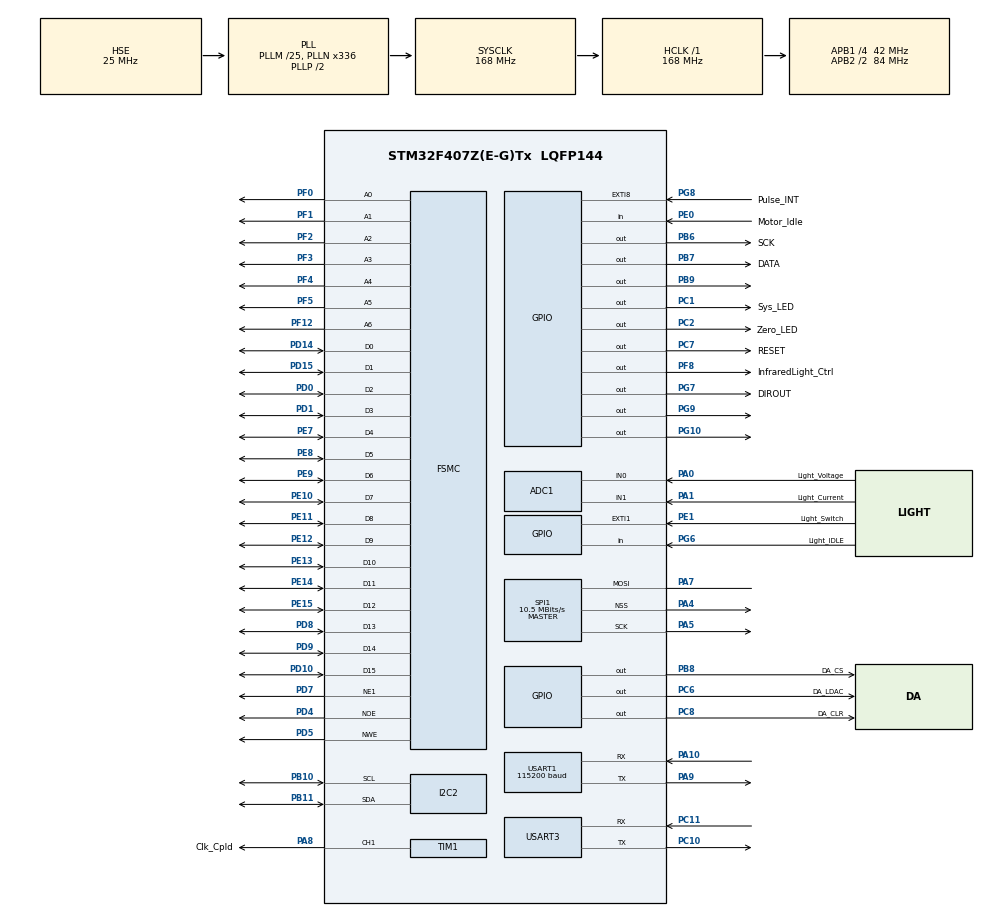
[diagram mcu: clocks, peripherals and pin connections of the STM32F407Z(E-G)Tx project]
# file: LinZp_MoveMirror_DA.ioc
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ADC1.Channel-0\#ChannelRegularConversion=ADC_CHANNEL_0
ADC1.NbrOfConversionFlag=1
ADC1.Rank-0\#ChannelRegularConversion=1
ADC1.SamplingTime-0\#ChannelRegularConversion=ADC_SAMPLETIME_3CYCLES
ADC1.master=1
Dma.I2C2_RX.0.Direction=DMA_PERIPH_TO_MEMORY
Dma.I2C2_RX.0.FIFOMode=DMA_FIFOMODE_DISABLE
Dma.I2C2_RX.0.Instance=DMA1_Stream2
Dma.I2C2_RX.0.MemDataAlignment=DMA_MDATAALIGN_BYTE
Dma.I2C2_RX.0.MemInc=DMA_MINC_ENABLE
Dma.I2C2_RX.0.Mode=DMA_NORMAL
Dma.I2C2_RX.0.PeriphDataAlignment=DMA_PDATAALIGN_BYTE
Dma.I2C2_RX.0.PeriphInc=DMA_PINC_DISABLE
Dma.I2C2_RX.0.Priority=DMA_PRIORITY_LOW
Dma.I2C2_TX.1.Direction=DMA_MEMORY_TO_PERIPH
Dma.I2C2_TX.1.FIFOMode=DMA_FIFOMODE_DISABLE
Dma.I2C2_TX.1.Instance=DMA1_Stream7
Dma.I2C2_TX.1.MemDataAlignment=DMA_MDATAALIGN_BYTE
Dma.I2C2_TX.1.MemInc=DMA_MINC_ENABLE
Dma.I2C2_TX.1.Mode=DMA_NORMAL
Dma.I2C2_TX.1.PeriphDataAlignment=DMA_PDATAALIGN_BYTE
Dma.I2C2_TX.1.PeriphInc=DMA_PINC_DISABLE
Dma.I2C2_TX.1.Priority=DMA_PRIORITY_LOW
Dma.Request0=I2C2_RX
Dma.Request1=I2C2_TX
Mcu.Family=STM32F4
Mcu.Name=STM32F407Z(E-G)Tx
Mcu.Package=LQFP144
NVIC.DMA1_Stream2_IRQn=true\:0\:0\:false\:false\:true\:false\:true
NVIC.DMA1_Stream7_IRQn=true\:0\:0\:false\:false\:false\:false\:false
NVIC.EXTI1_IRQn=true\:2\:0\:true\:false\:true\:true\:true
NVIC.EXTI9_5_IRQn=true\:1\:0\:true\:false\:true\:true\:true
NVIC.PriorityGroup=NVIC_PRIORITYGROUP_3
NVIC.TIM3_IRQn=true\:3\:0\:true\:false\:true\:true\:true
NVIC.TIM4_IRQn=true\:4\:0\:true\:false\:true\:true\:true
NVIC.USART1_IRQn=true\:0\:0\:true\:false\:true\:true\:true
NVIC.USART3_IRQn=true\:0\:0\:false\:false\:true\:true\:true
PA0-WKUP.GPIO_Label=Light_Voltage
PA0-WKUP.Signal=ADCx_IN0
PA1.GPIO_Label=Light_Current
PA1.Signal=ADCx_IN1
PA10.Mode=Asynchronous
PA10.Signal=USART1_RX
PA4.Mode=NSS_Signal_Hard_Output
PA4.Signal=SPI1_NSS
PA5.Mode=Simplex_Bidirectional_Master
PA5.Signal=SPI1_SCK
PA7.Mode=Simplex_Bidirectional_Master
PA7.Signal=SPI1_MOSI
PA8.GPIO_Label=Clk_Cpld
PA8.GPIO_Speed=GPIO_SPEED_FREQ_VERY_HIGH
PA8.Signal=S_TIM1_CH1
PA9.Mode=Asynchronous
PA9.Signal=USART1_TX
PB10.Mode=I2C
PB10.Signal=I2C2_SCL
PB11.Mode=I2C
PB11.Signal=I2C2_SDA
PB6.GPIO_Label=SCK
PB6.GPIO_Speed=GPIO_SPEED_FREQ_VERY_HIGH
PB6.Signal=GPIO_Output
PB7.GPIO_Label=DATA
PB7.GPIO_Speed=GPIO_SPEED_FREQ_VERY_HIGH
PB7.Signal=GPIO_Output
PB8.GPIO_Label=DA_CS
PB8.Signal=GPIO_Output
PB9.GPIO_PuPd=GPIO_NOPULL
PB9.GPIO_Speed=GPIO_SPEED_FREQ_VERY_HIGH
PB9.PinState=GPIO_PIN_RESET
PB9.Signal=GPIO_Output
PC1.GPIO_Label=Sys_LED
PC1.GPIO_PuPd=GPIO_PULLUP
PC1.GPIO_Speed=GPIO_SPEED_FREQ_HIGH
PC1.PinState=GPIO_PIN_SET
PC1.Signal=GPIO_Output
PC10.Mode=Asynchronous
PC10.Signal=USART3_TX
PC11.Mode=Asynchronous
PC11.Signal=USART3_RX
PC2.GPIO_Label=Zero_LED
PC2.GPIO_PuPd=GPIO_PULLUP
PC2.GPIO_Speed=GPIO_SPEED_FREQ_HIGH
PC2.PinState=GPIO_PIN_SET
PC2.Signal=GPIO_Output
PC6.GPIO_Label=DA_LDAC
PC6.Signal=GPIO_Output
PC7.GPIO_Label=RESET
PC7.Signal=GPIO_Output
PC8.GPIO_Label=DA_CLR
PC8.Signal=GPIO_Output
PD0.Signal=FSMC_D2_DA2
PD1.Signal=FSMC_D3_DA3
PD10.Signal=FSMC_D15_DA15
PD14.Signal=FSMC_D0_DA0
PD15.Signal=FSMC_D1_DA1
PD4.Signal=FSMC_NOE
PD5.Signal=FSMC_NWE
PD7.Mode=NorPsramChipSelect1_1
PD7.Signal=FSMC_NE1
PD8.Signal=FSMC_D13_DA13
PD9.Signal=FSMC_D14_DA14
PE0.GPIO_Label=Motor_Idle
PE0.GPIO_PuPd=GPIO_PULLUP
PE0.Signal=GPIO_Input
PE1.GPIO_Label=Light_Switch
PE1.Signal=GPXTI1
PE10.Signal=FSMC_D7_DA7
PE11.Signal=FSMC_D8_DA8
PE12.Signal=FSMC_D9_DA9
PE13.Signal=FSMC_D10_DA10
PE14.Signal=FSMC_D11_DA11
PE15.Signal=FSMC_D12_DA12
PE7.Signal=FSMC_D4_DA4
PE8.Signal=FSMC_D5_DA5
PE9.Signal=FSMC_D6_DA6
PF0.Signal=FSMC_A0
PF1.Signal=FSMC_A1
PF12.Signal=FSMC_A6
PF2.Signal=FSMC_A2
PF3.Signal=FSMC_A3
PF4.Signal=FSMC_A4
PF5.Signal=FSMC_A5
PF8.GPIO_Label=InfraredLight_Ctrl
PF8.GPIO_PuPd=GPIO_PULLDOWN
PF8.Signal=GPIO_Output
PG10.Signal=GPIO_Output
PG6.GPIO_Label=Light_IDLE
PG6.GPIO_PuPd=GPIO_PULLUP
PG6.Signal=GPIO_Input
PG7.GPIO_Label=DIROUT
PG7.GPIO_PuPd=GPIO_NOPULL
PG7.GPIO_Speed=GPIO_SPEED_FREQ_VERY_HIGH
PG7.Signal=GPIO_Output
PG8.GPIO_Label=Pulse_INT
PG8.Signal=GPXTI8
PG9.Signal=GPIO_Output
PH0-OSC_IN.Mode=HSE-External-Oscillator
PH0-OSC_IN.Signal=RCC_OSC_IN
PH1-OSC_OUT.Mode=HSE-External-Oscillator
PH1-OSC_OUT.Signal=RCC_OSC_OUT
ProjectManager.HeapSize=0x200
ProjectManager.StackSize=0x400
ProjectManager.TargetToolchain=MDK-ARM V5
RCC.48MHZClocksFreq_Value=84000000
RCC.AHBFreq_Value=168000000
RCC.APB1CLKDivider=RCC_HCLK_DIV4
RCC.APB1Freq_Value=42000000
RCC.APB1TimFreq_Value=84000000
RCC.APB2CLKDivider=RCC_HCLK_DIV2
RCC.APB2Freq_Value=84000000
RCC.APB2TimFreq_Value=168000000
RCC.CortexFreq_Value=168000000
RCC.HCLKFreq_Value=168000000
RCC.HSE_VALUE=25000000
RCC.HSI_VALUE=16000000
RCC.LSE_VALUE=32768
RCC.PLLM=25
RCC.PLLN=336
RCC.PLLSourceVirtual=RCC_PLLSOURCE_HSE
RCC.SYSCLKFreq_VALUE=168000000
RCC.SYSCLKSource=RCC_SYSCLKSOURCE_PLLCLK
RCC.VCOOutputFreq_Value=336000000
SH.ADCx_IN0.0=ADC1_IN0,IN0
SH.ADCx_IN1.0=ADC1_IN1,IN1
SH.FSMC_A0.0=FSMC_A0,7b-a1
SH.FSMC_A1.0=FSMC_A1,7b-a1
SH.FSMC_A2.0=FSMC_A2,7b-a1
SH.FSMC_A3.0=FSMC_A3,7b-a1
SH.FSMC_A4.0=FSMC_A4,7b-a1
SH.FSMC_A5.0=FSMC_A5,7b-a1
SH.FSMC_A6.0=FSMC_A6,7b-a1
SH.FSMC_D0_DA0.0=FSMC_D0,16b-d1
SH.FSMC_D10_DA10.0=FSMC_D10,16b-d1
SH.FSMC_D11_DA11.0=FSMC_D11,16b-d1
SH.FSMC_D12_DA12.0=FSMC_D12,16b-d1
SH.FSMC_D13_DA13.0=FSMC_D13,16b-d1
SH.FSMC_D14_DA14.0=FSMC_D14,16b-d1
SH.FSMC_D15_DA15.0=FSMC_D15,16b-d1
SH.FSMC_D1_DA1.0=FSMC_D1,16b-d1
SH.FSMC_D2_DA2.0=FSMC_D2,16b-d1
SH.FSMC_D3_DA3.0=FSMC_D3,16b-d1
SH.FSMC_D4_DA4.0=FSMC_D4,16b-d1
SH.FSMC_D5_DA5.0=FSMC_D5,16b-d1
SH.FSMC_D6_DA6.0=FSMC_D6,16b-d1
SH.FSMC_D7_DA7.0=FSMC_D7,16b-d1
SH.FSMC_D8_DA8.0=FSMC_D8,16b-d1
SH.FSMC_D9_DA9.0=FSMC_D9,16b-d1
SH.FSMC_NOE.0=FSMC_NOE,Sram1
SH.FSMC_NWE.0=FSMC_NWE,Sram1
SH.S_TIM1_CH1.0=TIM1_CH1,PWM Generation1 CH1
SPI1.BaudRatePrescaler=SPI_BAUDRATEPRESCALER_8
SPI1.CLKPhase=SPI_PHASE_2EDGE
SPI1.CalculateBaudRate=10.5 MBits/s
SPI1.Direction=SPI_DIRECTION_1LINE
SPI1.Mode=SPI_MODE_MASTER
SPI1.VirtualNSS=VM_NSSHARD
SPI1.VirtualType=VM_MASTER
TIM1.Channel-PWM\ Generation1\ CH1=TIM_CHANNEL_1
TIM1.Period=4
TIM1.Pulse-PWM\ Generation1\ CH1=2
TIM3.Period=1
TIM3.Prescaler=84
TIM4.Period=1
TIM4.Prescaler=84
USART1.BaudRate=115200
USART1.OverSampling=UART_OVERSAMPLING_8
USART1.VirtualMode=VM_ASYNC
USART3.OverSampling=UART_OVERSAMPLING_8
USART3.VirtualMode=VM_ASYNC
VP_TIM1_VS_ClockSourceINT.Mode=Internal
VP_TIM3_VS_ClockSourceINT.Mode=Internal
VP_TIM4_VS_ClockSourceINT.Mode=Internal
board=MoveMirrorFinal_pwm

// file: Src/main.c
/* USER CODE BEGIN Header */
/**
  ******************************************************************************
  * @file           : main.c
  * @brief          : Main program body
  ******************************************************************************
  * @attention
  *
  * <h2><center>&copy; Copyright (c) 2019 STMicroelectronics.
  * All rights reserved.</center></h2>
  *
  * This software component is licensed by ST under BSD 3-Clause license,
  * the "License"; You may not use this file except in compliance with the
  * License. You may obtain a copy of the License at:
  *                        opensource.org/licenses/BSD-3-Clause
  *
  ******************************************************************************
  */
/* USER CODE END Header */

#include "main.h"

/* USER CODE BEGIN Includes */
#include "sys.h"
/* USER CODE END Includes */

ADC_HandleTypeDef hadc1;

I2C_HandleTypeDef hi2c2;
DMA_HandleTypeDef hdma_i2c2_rx;
DMA_HandleTypeDef hdma_i2c2_tx;

SPI_HandleTypeDef hspi1;

TIM_HandleTypeDef htim1;
TIM_HandleTypeDef htim3;
TIM_HandleTypeDef htim4;

UART_HandleTypeDef huart1;
UART_HandleTypeDef huart3;

SRAM_HandleTypeDef hsram1;

/* USER CODE BEGIN PV */
/* Private variables ---------------------------------------------------------*/

/* USER CODE END PV */

void SystemClock_Config(void);
static void MX_GPIO_Init(void);
static void MX_DMA_Init(void);
static void MX_FSMC_Init(void);
static void MX_USART1_UART_Init(void);
static void MX_TIM3_Init(void);
static void MX_TIM4_Init(void);
static void MX_SPI1_Init(void);
static void MX_TIM1_Init(void);
static void MX_I2C2_Init(void);
static void MX_USART3_UART_Init(void);
static void MX_ADC1_Init(void);
/* USER CODE BEGIN PFP */
/* Private function prototypes -----------------------------------------------*/

/* USER CODE END PFP */

int main(void)
{

  /* MCU Configuration--------------------------------------------------------*/

  /* Reset of all peripherals, Initializes the Flash interface and the Systick. */
  HAL_Init();

  /* Configure the system clock */
  SystemClock_Config();

  /* Initialize all configured peripherals */
  MX_GPIO_Init();
  MX_DMA_Init();
  MX_FSMC_Init();
  MX_USART1_UART_Init();
  MX_TIM3_Init();
  MX_TIM4_Init();
  MX_SPI1_Init();
  MX_TIM1_Init();
  MX_I2C2_Init();
  MX_USART3_UART_Init();
  MX_ADC1_Init();
  /* USER CODE BEGIN 2 */
	DAC_init();

	HAL_UART_Receive_IT(&huart1,&Uart1_Data,1);//给接收到的数据定向，存在Uart1_Data_buffer[10]//__HAL_UART_ENABLE_IT(&huart1,UART_IT_RXNE); //开启接收完成中断
	HAL_UART_Receive_IT(&huart3,&Uart3_Data,1);//给接收到的数据定向，存在Uart1_Data_buffer[10]//__HAL_UART_ENABLE_IT(&huart1,UART_IT_RXNE); //开启接收完成中断

	//HAL_Delay_ms(15000);
	////////////////////////////////////////////////////////////////////////////
	HAL_TIM_PWM_Start(&htim1,TIM_CHANNEL_1);//提供给cpld时钟，实测33.6015MHz
	AD5245_Write(LightIntensity);//给AD5245写入初始值0x35=53，6.4v//8是10.6V//255是3.7v//0是12.43v
	//HAL_TIM_PWM_Start(&htim8,TIM_CHANNEL_1);//tim8开启 PWM 通道 1
	ResetCount = 0;       //复位计数
	ProcessFlag=ResetFlag;//开机复位
	//ProcessFlag=DebugFlag;//开机复位
	SystemReset();
	HAL_TIM_Base_Start_IT(&htim3);   //tim3中断开启,用于动镜的加速和减速
	HAL_TIM_Base_Start_IT(&htim4);   //tim4中断开启，用于调试信息输出，以及运动失调的复位
  /* USER CODE END 2 */

  /* Infinite loop */
  while (1)
  {

    /* USER CODE BEGIN 3 */
//		HAL_GPIO_WritePin(GPIOB, GPIO_PIN_9, GPIO_PIN_RESET);
//		HAL_Delay_ms(100);
//		HAL_GPIO_WritePin(GPIOB, GPIO_PIN_9, GPIO_PIN_RESET);
//		HAL_Delay_ms(100);
//AD5245_Write(0);//给AD5245写入初始值0x35=53，6.4v//8是10.6V//255是3.7v//0是12.43v
//GetLightStatus();

//HAL_Delay_ms(100);
//	Motor_Idle=HAL_GPIO_ReadPin(Motor_Idle_GPIO_Port,Motor_Idle_Pin);
//	Light_Idle=HAL_GPIO_ReadPin(Light_IDLE_GPIO_Port,Light_IDLE_Pin);
//char str[25];
//sprintf(str,"who is your daddy\r\n");
//HAL_UART_Transmit(&huart3,(uint8_t*)str,strlen(str),1000);

//	HAL_Delay_ms(10);
//	HAL_GPIO_WritePin(GPIOB, GPIO_PIN_6, GPIO_PIN_RESET); //SHT_SCK=1
//	HAL_GPIO_WritePin(GPIOB, GPIO_PIN_7, GPIO_PIN_RESET);//SHT_SCK=0
//	HAL_GPIO_WritePin(GPIOB, GPIO_PIN_9, GPIO_PIN_RESET);
//
//
//	HAL_Delay_ms(10);
//	HAL_GPIO_WritePin(GPIOB, GPIO_PIN_6, GPIO_PIN_SET); //SHT_SCK=1
//	HAL_GPIO_WritePin(GPIOB, GPIO_PIN_7, GPIO_PIN_SET);//SHT_SCK=0
//	HAL_GPIO_WritePin(GPIOB, GPIO_PIN_9, GPIO_PIN_SET);

//float *p_temp,*p_humi;
//p_temp=&temp;
//p_humi=&humi;
//ShtMeasure(p_temp,p_humi);

//SetOutput(-584287);

//uint8_t ADDR_AD5245_Write = 0x58;//01011000
//uint8_t data = 0x35;//53
//HAL_I2C_Mem_Write(&hi2c1, ADDR_AD5245_Write, 0, I2C_MEMADD_SIZE_8BIT,&data,1,0xff);
//HAL_I2C_Master_Transmit_DMA(&hi2c1,ADDR_AD5245_Write,&data,1);

//ADC_Value4 = Get_Adc(4);
//ADC_Value5 = Get_Adc(5);

//HAL_Delay(5);
//HAL_I2C_Mem_Write(&hi2c1, ADDR_24LCxx_Read, 0, I2C_MEMADD_SIZE_8BIT,&val,1,0xff);

//SetOutput(300000);
//Write_AD_5791(320000);
//HAL_Delay_ms(1000);
//HAL_GPIO_WritePin(GPIOC, GPIO_PIN_1, GPIO_PIN_RESET);
//HAL_Delay_ms(1000);
//HAL_GPIO_WritePin(GPIOC, GPIO_PIN_1, GPIO_PIN_SET);
  }
  /* USER CODE END 3 */
}

void SystemClock_Config(void)
{
  RCC_OscInitTypeDef RCC_OscInitStruct = {0};
  RCC_ClkInitTypeDef RCC_ClkInitStruct = {0};

  /** Configure the main internal regulator output voltage
  */
  __HAL_RCC_PWR_CLK_ENABLE();
  __HAL_PWR_VOLTAGESCALING_CONFIG(PWR_REGULATOR_VOLTAGE_SCALE1);
  /** Initializes the CPU, AHB and APB busses clocks
  */
  RCC_OscInitStruct.OscillatorType = RCC_OSCILLATORTYPE_HSE;
  RCC_OscInitStruct.HSEState = RCC_HSE_ON;
  RCC_OscInitStruct.PLL.PLLState = RCC_PLL_ON;
  RCC_OscInitStruct.PLL.PLLSource = RCC_PLLSOURCE_HSE;
  RCC_OscInitStruct.PLL.PLLM = 25;
  RCC_OscInitStruct.PLL.PLLN = 336;
  RCC_OscInitStruct.PLL.PLLP = RCC_PLLP_DIV2;
  RCC_OscInitStruct.PLL.PLLQ = 4;
  if (HAL_RCC_OscConfig(&RCC_OscInitStruct) != HAL_OK)
  {
    Error_Handler();
  }
  /** Initializes the CPU, AHB and APB busses clocks
  */
  RCC_ClkInitStruct.ClockType = RCC_CLOCKTYPE_HCLK|RCC_CLOCKTYPE_SYSCLK
                              |RCC_CLOCKTYPE_PCLK1|RCC_CLOCKTYPE_PCLK2;
  RCC_ClkInitStruct.SYSCLKSource = RCC_SYSCLKSOURCE_PLLCLK;
  RCC_ClkInitStruct.AHBCLKDivider = RCC_SYSCLK_DIV1;
  RCC_ClkInitStruct.APB1CLKDivider = RCC_HCLK_DIV4;
  RCC_ClkInitStruct.APB2CLKDivider = RCC_HCLK_DIV2;

  if (HAL_RCC_ClockConfig(&RCC_ClkInitStruct, FLASH_LATENCY_5) != HAL_OK)
  {
    Error_Handler();
  }
}

static void MX_ADC1_Init(void)
{

  ADC_ChannelConfTypeDef sConfig = {0};

  /** Configure the global features of the ADC (Clock, Resolution, Data Alignment and number of conversion)
  */
  hadc1.Instance = ADC1;
  hadc1.Init.ClockPrescaler = ADC_CLOCK_SYNC_PCLK_DIV4;
  hadc1.Init.Resolution = ADC_RESOLUTION_12B;
  hadc1.Init.ScanConvMode = DISABLE;
  hadc1.Init.ContinuousConvMode = DISABLE;
  hadc1.Init.DiscontinuousConvMode = DISABLE;
  hadc1.Init.ExternalTrigConvEdge = ADC_EXTERNALTRIGCONVEDGE_NONE;
  hadc1.Init.ExternalTrigConv = ADC_SOFTWARE_START;
  hadc1.Init.DataAlign = ADC_DATAALIGN_RIGHT;
  hadc1.Init.NbrOfConversion = 1;
  hadc1.Init.DMAContinuousRequests = DISABLE;
  hadc1.Init.EOCSelection = ADC_EOC_SINGLE_CONV;
  if (HAL_ADC_Init(&hadc1) != HAL_OK)
  {
    Error_Handler();
  }
  /** Configure for the selected ADC regular channel its corresponding rank in the sequencer and its sample time.
  */
  sConfig.Channel = ADC_CHANNEL_0;
  sConfig.Rank = 1;
  sConfig.SamplingTime = ADC_SAMPLETIME_3CYCLES;
  if (HAL_ADC_ConfigChannel(&hadc1, &sConfig) != HAL_OK)
  {
    Error_Handler();
  }

}

static void MX_I2C2_Init(void)
{

  hi2c2.Instance = I2C2;
  hi2c2.Init.ClockSpeed = 100000;
  hi2c2.Init.DutyCycle = I2C_DUTYCYCLE_2;
  hi2c2.Init.OwnAddress1 = 0;
  hi2c2.Init.AddressingMode = I2C_ADDRESSINGMODE_7BIT;
  hi2c2.Init.DualAddressMode = I2C_DUALADDRESS_DISABLE;
  hi2c2.Init.OwnAddress2 = 0;
  hi2c2.Init.GeneralCallMode = I2C_GENERALCALL_DISABLE;
  hi2c2.Init.NoStretchMode = I2C_NOSTRETCH_DISABLE;
  if (HAL_I2C_Init(&hi2c2) != HAL_OK)
  {
    Error_Handler();
  }

}

static void MX_SPI1_Init(void)
{

  /* SPI1 parameter configuration*/
  hspi1.Instance = SPI1;
  hspi1.Init.Mode = SPI_MODE_MASTER;
  hspi1.Init.Direction = SPI_DIRECTION_1LINE;
  hspi1.Init.DataSize = SPI_DATASIZE_8BIT;
  hspi1.Init.CLKPolarity = SPI_POLARITY_LOW;
  hspi1.Init.CLKPhase = SPI_PHASE_2EDGE;
  hspi1.Init.NSS = SPI_NSS_HARD_OUTPUT;
  hspi1.Init.BaudRatePrescaler = SPI_BAUDRATEPRESCALER_8;
  hspi1.Init.FirstBit = SPI_FIRSTBIT_MSB;
  hspi1.Init.TIMode = SPI_TIMODE_DISABLE;
  hspi1.Init.CRCCalculation = SPI_CRCCALCULATION_DISABLE;
  hspi1.Init.CRCPolynomial = 10;
  if (HAL_SPI_Init(&hspi1) != HAL_OK)
  {
    Error_Handler();
  }

}

static void MX_TIM1_Init(void)
{

  TIM_ClockConfigTypeDef sClockSourceConfig = {0};
  TIM_MasterConfigTypeDef sMasterConfig = {0};
  TIM_OC_InitTypeDef sConfigOC = {0};
  TIM_BreakDeadTimeConfigTypeDef sBreakDeadTimeConfig = {0};

  htim1.Instance = TIM1;
  htim1.Init.Prescaler = 0;
  htim1.Init.CounterMode = TIM_COUNTERMODE_UP;
  htim1.Init.Period = 4;
  htim1.Init.ClockDivision = TIM_CLOCKDIVISION_DIV1;
  htim1.Init.RepetitionCounter = 0;
  htim1.Init.AutoReloadPreload = TIM_AUTORELOAD_PRELOAD_DISABLE;
  if (HAL_TIM_Base_Init(&htim1) != HAL_OK)
  {
    Error_Handler();
  }
  sClockSourceConfig.ClockSource = TIM_CLOCKSOURCE_INTERNAL;
  if (HAL_TIM_ConfigClockSource(&htim1, &sClockSourceConfig) != HAL_OK)
  {
    Error_Handler();
  }
  if (HAL_TIM_PWM_Init(&htim1) != HAL_OK)
  {
    Error_Handler();
  }
  sMasterConfig.MasterOutputTrigger = TIM_TRGO_RESET;
  sMasterConfig.MasterSlaveMode = TIM_MASTERSLAVEMODE_DISABLE;
  if (HAL_TIMEx_MasterConfigSynchronization(&htim1, &sMasterConfig) != HAL_OK)
  {
    Error_Handler();
  }
  sConfigOC.OCMode = TIM_OCMODE_PWM1;
  sConfigOC.Pulse = 2;
  sConfigOC.OCPolarity = TIM_OCPOLARITY_HIGH;
  sConfigOC.OCNPolarity = TIM_OCNPOLARITY_HIGH;
  sConfigOC.OCFastMode = TIM_OCFAST_DISABLE;
  sConfigOC.OCIdleState = TIM_OCIDLESTATE_RESET;
  sConfigOC.OCNIdleState = TIM_OCNIDLESTATE_RESET;
  if (HAL_TIM_PWM_ConfigChannel(&htim1, &sConfigOC, TIM_CHANNEL_1) != HAL_OK)
  {
    Error_Handler();
  }
  sBreakDeadTimeConfig.OffStateRunMode = TIM_OSSR_DISABLE;
  sBreakDeadTimeConfig.OffStateIDLEMode = TIM_OSSI_DISABLE;
  sBreakDeadTimeConfig.LockLevel = TIM_LOCKLEVEL_OFF;
  sBreakDeadTimeConfig.DeadTime = 0;
  sBreakDeadTimeConfig.BreakState = TIM_BREAK_DISABLE;
  sBreakDeadTimeConfig.BreakPolarity = TIM_BREAKPOLARITY_HIGH;
  sBreakDeadTimeConfig.AutomaticOutput = TIM_AUTOMATICOUTPUT_DISABLE;
  if (HAL_TIMEx_ConfigBreakDeadTime(&htim1, &sBreakDeadTimeConfig) != HAL_OK)
  {
    Error_Handler();
  }
  HAL_TIM_MspPostInit(&htim1);

}

static void MX_TIM3_Init(void)
{

  TIM_ClockConfigTypeDef sClockSourceConfig = {0};
  TIM_MasterConfigTypeDef sMasterConfig = {0};

  htim3.Instance = TIM3;
  htim3.Init.Prescaler = 84;
  htim3.Init.CounterMode = TIM_COUNTERMODE_UP;
  htim3.Init.Period = 1;
  htim3.Init.ClockDivision = TIM_CLOCKDIVISION_DIV1;
  htim3.Init.AutoReloadPreload = TIM_AUTORELOAD_PRELOAD_DISABLE;
  if (HAL_TIM_Base_Init(&htim3) != HAL_OK)
  {
    Error_Handler();
  }
  sClockSourceConfig.ClockSource = TIM_CLOCKSOURCE_INTERNAL;
  if (HAL_TIM_ConfigClockSource(&htim3, &sClockSourceConfig) != HAL_OK)
  {
    Error_Handler();
  }
  sMasterConfig.MasterOutputTrigger = TIM_TRGO_RESET;
  sMasterConfig.MasterSlaveMode = TIM_MASTERSLAVEMODE_DISABLE;
  if (HAL_TIMEx_MasterConfigSynchronization(&htim3, &sMasterConfig) != HAL_OK)
  {
    Error_Handler();
  }

}

static void MX_TIM4_Init(void)
{

  TIM_ClockConfigTypeDef sClockSourceConfig = {0};
  TIM_MasterConfigTypeDef sMasterConfig = {0};

  htim4.Instance = TIM4;
  htim4.Init.Prescaler = 84;
  htim4.Init.CounterMode = TIM_COUNTERMODE_UP;
  htim4.Init.Period = 1;
  htim4.Init.ClockDivision = TIM_CLOCKDIVISION_DIV1;
  htim4.Init.AutoReloadPreload = TIM_AUTORELOAD_PRELOAD_DISABLE;
  if (HAL_TIM_Base_Init(&htim4) != HAL_OK)
  {
    Error_Handler();
  }
  sClockSourceConfig.ClockSource = TIM_CLOCKSOURCE_INTERNAL;
  if (HAL_TIM_ConfigClockSource(&htim4, &sClockSourceConfig) != HAL_OK)
  {
    Error_Handler();
  }
  sMasterConfig.MasterOutputTrigger = TIM_TRGO_RESET;
  sMasterConfig.MasterSlaveMode = TIM_MASTERSLAVEMODE_DISABLE;
  if (HAL_TIMEx_MasterConfigSynchronization(&htim4, &sMasterConfig) != HAL_OK)
  {
    Error_Handler();
  }

}

static void MX_USART1_UART_Init(void)
{

  huart1.Instance = USART1;
  huart1.Init.BaudRate = 115200;
  huart1.Init.WordLength = UART_WORDLENGTH_8B;
  huart1.Init.StopBits = UART_STOPBITS_1;
  huart1.Init.Parity = UART_PARITY_NONE;
  huart1.Init.Mode = UART_MODE_TX_RX;
  huart1.Init.HwFlowCtl = UART_HWCONTROL_NONE;
  huart1.Init.OverSampling = UART_OVERSAMPLING_8;
  if (HAL_UART_Init(&huart1) != HAL_OK)
  {
    Error_Handler();
  }

}

static void MX_USART3_UART_Init(void)
{

  huart3.Instance = USART3;
  huart3.Init.BaudRate = 115200;
  huart3.Init.WordLength = UART_WORDLENGTH_8B;
  huart3.Init.StopBits = UART_STOPBITS_1;
  huart3.Init.Parity = UART_PARITY_NONE;
  huart3.Init.Mode = UART_MODE_TX_RX;
  huart3.Init.HwFlowCtl = UART_HWCONTROL_NONE;
  huart3.Init.OverSampling = UART_OVERSAMPLING_8;
  if (HAL_UART_Init(&huart3) != HAL_OK)
  {
    Error_Handler();
  }

}

static void MX_DMA_Init(void)
{
  /* DMA controller clock enable */
  __HAL_RCC_DMA1_CLK_ENABLE();

  /* DMA interrupt init */
  /* DMA1_Stream2_IRQn interrupt configuration */
  HAL_NVIC_SetPriority(DMA1_Stream2_IRQn, 0, 0);
  HAL_NVIC_EnableIRQ(DMA1_Stream2_IRQn);
  /* DMA1_Stream7_IRQn interrupt configuration */
  HAL_NVIC_SetPriority(DMA1_Stream7_IRQn, 0, 0);
  HAL_NVIC_EnableIRQ(DMA1_Stream7_IRQn);

}

static void MX_GPIO_Init(void)
{
  GPIO_InitTypeDef GPIO_InitStruct = {0};

  /* GPIO Ports Clock Enable */
  __HAL_RCC_GPIOF_CLK_ENABLE();
  __HAL_RCC_GPIOH_CLK_ENABLE();
  __HAL_RCC_GPIOC_CLK_ENABLE();
  __HAL_RCC_GPIOA_CLK_ENABLE();
  __HAL_RCC_GPIOE_CLK_ENABLE();
  __HAL_RCC_GPIOB_CLK_ENABLE();
  __HAL_RCC_GPIOD_CLK_ENABLE();
  __HAL_RCC_GPIOG_CLK_ENABLE();

  /*Configure GPIO pin Output Level */
  HAL_GPIO_WritePin(InfraredLight_Ctrl_GPIO_Port, InfraredLight_Ctrl_Pin, GPIO_PIN_RESET);

  /*Configure GPIO pin Output Level */
  HAL_GPIO_WritePin(GPIOC, Sys_LED_Pin|Zero_LED_Pin, GPIO_PIN_SET);

  /*Configure GPIO pin Output Level */
  HAL_GPIO_WritePin(GPIOG, DIROUT_Pin|GPIO_PIN_9|GPIO_PIN_10, GPIO_PIN_RESET);

  /*Configure GPIO pin Output Level */
  HAL_GPIO_WritePin(GPIOC, DA_LDAC_Pin|RESET_Pin|DA_CLR_Pin, GPIO_PIN_RESET);

  /*Configure GPIO pin Output Level */
  HAL_GPIO_WritePin(GPIOB, SCK_Pin|DATA_Pin|DA_CS_Pin|GPIO_PIN_9, GPIO_PIN_RESET);

  /*Configure GPIO pin : InfraredLight_Ctrl_Pin */
  GPIO_InitStruct.Pin = InfraredLight_Ctrl_Pin;
  GPIO_InitStruct.Mode = GPIO_MODE_OUTPUT_PP;
  GPIO_InitStruct.Pull = GPIO_PULLDOWN;
  GPIO_InitStruct.Speed = GPIO_SPEED_FREQ_LOW;
  HAL_GPIO_Init(InfraredLight_Ctrl_GPIO_Port, &GPIO_InitStruct);

  /*Configure GPIO pins : Sys_LED_Pin Zero_LED_Pin */
  GPIO_InitStruct.Pin = Sys_LED_Pin|Zero_LED_Pin;
  GPIO_InitStruct.Mode = GPIO_MODE_OUTPUT_PP;
  GPIO_InitStruct.Pull = GPIO_PULLUP;
  GPIO_InitStruct.Speed = GPIO_SPEED_FREQ_HIGH;
  HAL_GPIO_Init(GPIOC, &GPIO_InitStruct);

  /*Configure GPIO pin : Light_IDLE_Pin */
  GPIO_InitStruct.Pin = Light_IDLE_Pin;
  GPIO_InitStruct.Mode = GPIO_MODE_INPUT;
  GPIO_InitStruct.Pull = GPIO_PULLUP;
  HAL_GPIO_Init(Light_IDLE_GPIO_Port, &GPIO_InitStruct);

  /*Configure GPIO pin : DIROUT_Pin */
  GPIO_InitStruct.Pin = DIROUT_Pin;
  GPIO_InitStruct.Mode = GPIO_MODE_OUTPUT_PP;
  GPIO_InitStruct.Pull = GPIO_NOPULL;
  GPIO_InitStruct.Speed = GPIO_SPEED_FREQ_VERY_HIGH;
  HAL_GPIO_Init(DIROUT_GPIO_Port, &GPIO_InitStruct);

  /*Configure GPIO pin : Pulse_INT_Pin */
  GPIO_InitStruct.Pin = Pulse_INT_Pin;
  GPIO_InitStruct.Mode = GPIO_MODE_IT_RISING;
  GPIO_InitStruct.Pull = GPIO_NOPULL;
  HAL_GPIO_Init(Pulse_INT_GPIO_Port, &GPIO_InitStruct);

  /*Configure GPIO pins : DA_LDAC_Pin RESET_Pin DA_CLR_Pin */
  GPIO_InitStruct.Pin = DA_LDAC_Pin|RESET_Pin|DA_CLR_Pin;
  GPIO_InitStruct.Mode = GPIO_MODE_OUTPUT_PP;
  GPIO_InitStruct.Pull = GPIO_NOPULL;
  GPIO_InitStruct.Speed = GPIO_SPEED_FREQ_LOW;
  HAL_GPIO_Init(GPIOC, &GPIO_InitStruct);

  /*Configure GPIO pins : PG9 PG10 */
  GPIO_InitStruct.Pin = GPIO_PIN_9|GPIO_PIN_10;
  GPIO_InitStruct.Mode = GPIO_MODE_OUTPUT_PP;
  GPIO_InitStruct.Pull = GPIO_NOPULL;
  GPIO_InitStruct.Speed = GPIO_SPEED_FREQ_LOW;
  HAL_GPIO_Init(GPIOG, &GPIO_InitStruct);

  /*Configure GPIO pins : SCK_Pin DATA_Pin PB9 */
  GPIO_InitStruct.Pin = SCK_Pin|DATA_Pin|GPIO_PIN_9;
  GPIO_InitStruct.Mode = GPIO_MODE_OUTPUT_PP;
  GPIO_InitStruct.Pull = GPIO_NOPULL;
  GPIO_InitStruct.Speed = GPIO_SPEED_FREQ_VERY_HIGH;
  HAL_GPIO_Init(GPIOB, &GPIO_InitStruct);

  /*Configure GPIO pin : DA_CS_Pin */
  GPIO_InitStruct.Pin = DA_CS_Pin;
  GPIO_InitStruct.Mode = GPIO_MODE_OUTPUT_PP;
  GPIO_InitStruct.Pull = GPIO_NOPULL;
  GPIO_InitStruct.Speed = GPIO_SPEED_FREQ_LOW;
  HAL_GPIO_Init(DA_CS_GPIO_Port, &GPIO_InitStruct);

  /*Configure GPIO pin : Motor_Idle_Pin */
  GPIO_InitStruct.Pin = Motor_Idle_Pin;
  GPIO_InitStruct.Mode = GPIO_MODE_INPUT;
  GPIO_InitStruct.Pull = GPIO_PULLUP;
  HAL_GPIO_Init(Motor_Idle_GPIO_Port, &GPIO_InitStruct);

  /*Configure GPIO pin : Light_Switch_Pin */
  GPIO_InitStruct.Pin = Light_Switch_Pin;
  GPIO_InitStruct.Mode = GPIO_MODE_IT_RISING;
  GPIO_InitStruct.Pull = GPIO_NOPULL;
  HAL_GPIO_Init(Light_Switch_GPIO_Port, &GPIO_InitStruct);

  /* EXTI interrupt init*/
  HAL_NVIC_SetPriority(EXTI1_IRQn, 2, 0);
  HAL_NVIC_EnableIRQ(EXTI1_IRQn);

  HAL_NVIC_SetPriority(EXTI9_5_IRQn, 1, 0);
  HAL_NVIC_EnableIRQ(EXTI9_5_IRQn);

}

/* FSMC initialization function */
static void MX_FSMC_Init(void)
{

  FSMC_NORSRAM_TimingTypeDef Timing = {0};

  /** Perform the SRAM1 memory initialization sequence
  */
  hsram1.Instance = FSMC_NORSRAM_DEVICE;
  hsram1.Extended = FSMC_NORSRAM_EXTENDED_DEVICE;
  /* hsram1.Init */
  hsram1.Init.NSBank = FSMC_NORSRAM_BANK1;
  hsram1.Init.DataAddressMux = FSMC_DATA_ADDRESS_MUX_DISABLE;
  hsram1.Init.MemoryType = FSMC_MEMORY_TYPE_SRAM;
  hsram1.Init.MemoryDataWidth = FSMC_NORSRAM_MEM_BUS_WIDTH_16;
  hsram1.Init.BurstAccessMode = FSMC_BURST_ACCESS_MODE_DISABLE;
  hsram1.Init.WaitSignalPolarity = FSMC_WAIT_SIGNAL_POLARITY_LOW;
  hsram1.Init.WrapMode = FSMC_WRAP_MODE_DISABLE;
  hsram1.Init.WaitSignalActive = FSMC_WAIT_TIMING_BEFORE_WS;
  hsram1.Init.WriteOperation = FSMC_WRITE_OPERATION_DISABLE;
  hsram1.Init.WaitSignal = FSMC_WAIT_SIGNAL_DISABLE;
  hsram1.Init.ExtendedMode = FSMC_EXTENDED_MODE_DISABLE;
  hsram1.Init.AsynchronousWait = FSMC_ASYNCHRONOUS_WAIT_DISABLE;
  hsram1.Init.WriteBurst = FSMC_WRITE_BURST_DISABLE;
  hsram1.Init.PageSize = FSMC_PAGE_SIZE_NONE;
  /* Timing */
  Timing.AddressSetupTime = 15;
  Timing.AddressHoldTime = 15;
  Timing.DataSetupTime = 255;
  Timing.BusTurnAroundDuration = 15;
  Timing.CLKDivision = 16;
  Timing.DataLatency = 17;
  Timing.AccessMode = FSMC_ACCESS_MODE_A;
  /* ExtTiming */

  if (HAL_SRAM_Init(&hsram1, &Timing, NULL) != HAL_OK)
  {
    Error_Handler( );
  }

}

void Error_Handler(void)
{
  while(1)
  {
  }
}

/************************ (C) COPYRIGHT STMicroelectronics *****END OF FILE****/
